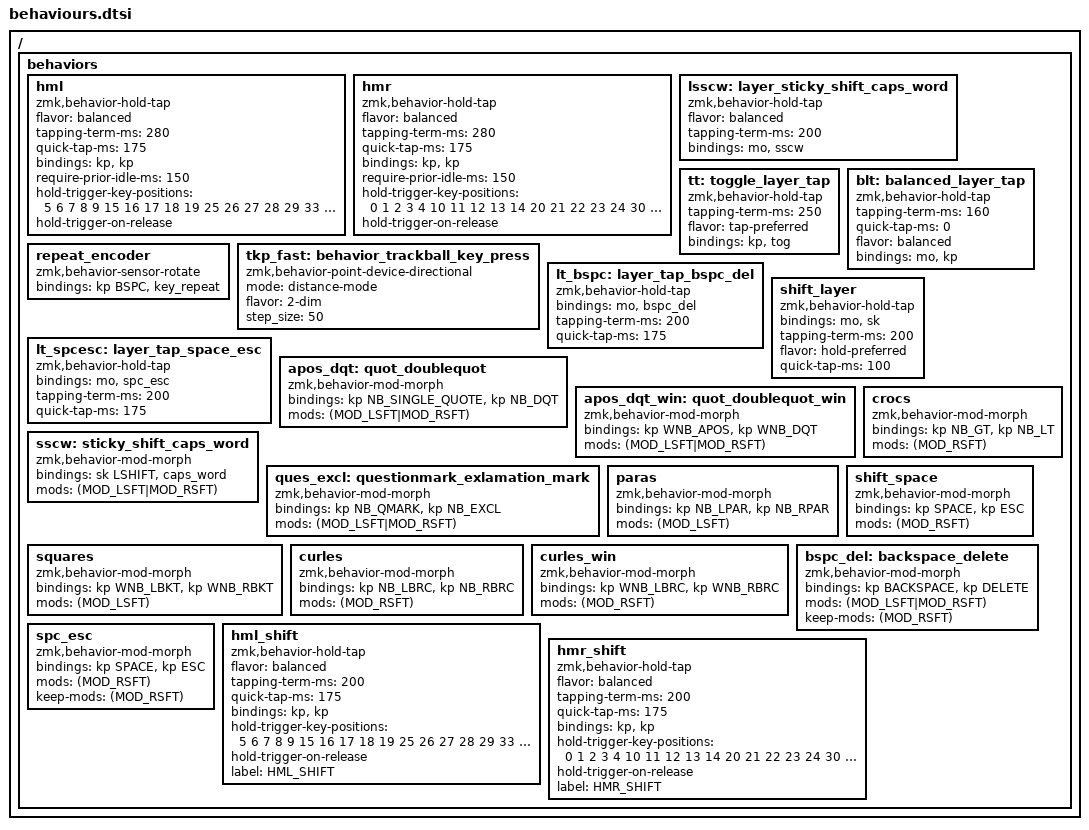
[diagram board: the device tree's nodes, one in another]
/ {
    behaviors {
        hml: hml {
            compatible = "zmk,behavior-hold-tap";
            #binding-cells = <2>;
            flavor = "balanced";
            tapping-term-ms = <280>;
            quick-tap-ms = <175>;                // repeat on tap-into-hold
            bindings = <&kp>, <&kp>;

            require-prior-idle-ms = <150>;
            hold-trigger-key-positions = <5 6 7 8 9 15 16 17 18 19 25 26 27 28 29 33 34 31 32>;
            hold-trigger-on-release;
        };

        hmr: hmr {
            compatible = "zmk,behavior-hold-tap";
            #binding-cells = <2>;
            flavor = "balanced";
            tapping-term-ms = <280>;
            quick-tap-ms = <175>;                // repeat on tap-into-hold
            bindings = <&kp>, <&kp>;

            require-prior-idle-ms = <150>;
            hold-trigger-key-positions = <0 1 2 3 4 10 11 12 13 14 20 21 22 23 24 30 31 32 34 33>;
            hold-trigger-on-release;
        };

        lsscw: layer_sticky_shift_caps_word {
            compatible = "zmk,behavior-hold-tap";
            #binding-cells = <2>;
            flavor = "balanced";
            tapping-term-ms = <200>;
            bindings = <&mo>, <&sscw>;
        };

        tt: toggle_layer_tap {
            compatible = "zmk,behavior-hold-tap";
            #binding-cells = <2>;
            tapping-term-ms = <250>;
            flavor = "tap-preferred";
            bindings = <&kp>, <&tog>;
        };

        blt: balanced_layer_tap {
            compatible = "zmk,behavior-hold-tap";
            #binding-cells = <2>;
            tapping-term-ms = <160>;
            quick-tap-ms = <0>;
            flavor = "balanced";
            bindings = <&mo>, <&kp>;
        };

        repeat_encoder: repeat_encoder {
            compatible = "zmk,behavior-sensor-rotate";
            #sensor-binding-cells = <0>;
            bindings = <&kp BSPC>, <&key_repeat>;
        };

        tkp_fast: behavior_trackball_key_press {
            compatible = "zmk,behavior-point-device-directional";
            #trackball-binding-cells = <4>;
            mode = "distance-mode";
            flavor = "2-dim";
            step_size = <50>;
        };

        lt_bspc: layer_tap_bspc_del {
            compatible = "zmk,behavior-hold-tap";
            #binding-cells = <2>;
            bindings = <&mo>, <&bspc_del>;

            tapping-term-ms = <200>;
            quick-tap-ms = <175>;
        };

        shift_layer: shift_layer {
            compatible = "zmk,behavior-hold-tap";
            #binding-cells = <2>;
            bindings = <&mo>, <&sk>;

            tapping-term-ms = <200>;
            flavor = "hold-preferred";
            quick-tap-ms = <100>;
        };

        lt_spcesc: layer_tap_space_esc {
            compatible = "zmk,behavior-hold-tap";
            #binding-cells = <2>;
            bindings = <&mo>, <&spc_esc>;

            tapping-term-ms = <200>;
            quick-tap-ms = <175>;
        };

        apos_dqt: quot_doublequot {
            compatible = "zmk,behavior-mod-morph";
            #binding-cells = <0>;
            bindings = <&kp NB_SINGLE_QUOTE>, <&kp NB_DQT>;

            mods = <(MOD_LSFT|MOD_RSFT)>;
        };

        apos_dqt_win: quot_doublequot_win {
            compatible = "zmk,behavior-mod-morph";
            #binding-cells = <0>;
            bindings = <&kp WNB_APOS>, <&kp WNB_DQT>;

            mods = <(MOD_LSFT|MOD_RSFT)>;
        };

        sscw: sticky_shift_caps_word {
            compatible = "zmk,behavior-mod-morph";
            #binding-cells = <0>;
            bindings = <&sk LSHIFT>, <&caps_word>;

            mods = <(MOD_LSFT|MOD_RSFT)>;
        };

        ques_excl: questionmark_exlamation_mark {
            compatible = "zmk,behavior-mod-morph";
            #binding-cells = <0>;
            bindings = <&kp NB_QMARK>, <&kp NB_EXCL>;

            mods = <(MOD_LSFT|MOD_RSFT)>;
        };

        paras: paras {
            compatible = "zmk,behavior-mod-morph";
            bindings = <&kp NB_LPAR>, <&kp NB_RPAR>;

            #binding-cells = <0>;
            mods = <(MOD_LSFT)>;
        };

        squares: squares {
            compatible = "zmk,behavior-mod-morph";
            bindings = <&kp WNB_LBKT>, <&kp WNB_RBKT>;

            #binding-cells = <0>;
            mods = <(MOD_LSFT)>;
        };

        curles: curles {
            compatible = "zmk,behavior-mod-morph";
            bindings = <&kp NB_LBRC>, <&kp NB_RBRC>;

            #binding-cells = <0>;
            mods = <(MOD_RSFT)>;
        };

        curles_win: curles_win {
            compatible = "zmk,behavior-mod-morph";
            bindings = <&kp WNB_LBRC>, <&kp WNB_RBRC>;

            #binding-cells = <0>;
            mods = <(MOD_RSFT)>;
        };

        crocs: crocs {
            compatible = "zmk,behavior-mod-morph";
            bindings = <&kp NB_GT>, <&kp NB_LT>;

            #binding-cells = <0>;
            mods = <(MOD_RSFT)>;
        };

        shift_space: shift_space {
            compatible = "zmk,behavior-mod-morph";
            bindings = <&kp SPACE>, <&kp ESC>;

            #binding-cells = <0>;
            mods = <(MOD_RSFT)>;
        };

        bspc_del: backspace_delete {
            compatible = "zmk,behavior-mod-morph";
            #binding-cells = <0>;
            bindings = <&kp BACKSPACE>, <&kp DELETE>;

            mods = <(MOD_LSFT|MOD_RSFT)>;
            keep-mods = <(MOD_RSFT)>;
        };

        spc_esc: spc_esc {
            compatible = "zmk,behavior-mod-morph";
            bindings = <&kp SPACE>, <&kp ESC>;

            #binding-cells = <0>;
            mods = <(MOD_RSFT)>;
            keep-mods = <(MOD_RSFT)>;
        };

        hml_shift: hml_shift {
            compatible = "zmk,behavior-hold-tap";
            #binding-cells = <2>;
            flavor = "balanced";
            tapping-term-ms = <200>;
            quick-tap-ms = <175>;
            bindings = <&kp>, <&kp>;

            hold-trigger-key-positions = <5 6 7 8 9 15 16 17 18 19 25 26 27 28 29 33 34 31 32>;
            hold-trigger-on-release;
            label = "HML_SHIFT";
        };

        hmr_shift: hmr_shift {
            compatible = "zmk,behavior-hold-tap";
            #binding-cells = <2>;
            flavor = "balanced";
            tapping-term-ms = <200>;
            quick-tap-ms = <175>;
            bindings = <&kp>, <&kp>;

            hold-trigger-key-positions = <0 1 2 3 4 10 11 12 13 14 20 21 22 23 24 30 31 32 34 33>;
            hold-trigger-on-release;
            label = "HMR_SHIFT";
        };
    };
};
